LIN_description_file;
LIN_protocol_version = "2.1";
LIN_language_version = "2.1";
LIN_speed = 19.2 kbps;

Nodes {
  Master: MasterNode, 5 ms, 0.1 ms ;
  Slaves: Gateway ;
}

Signals {
  Cluster1Potentiometer1: 8, 0, Gateway, MasterNode;
  Cluster1LightSensor1: 8, 0, Gateway, MasterNode;
  Cluster1Potentiometer2: 8, 0, Gateway, MasterNode;
  Cluster2PotentiometerA: 8, 0, Gateway, MasterNode;
  Cluster2LightSensorA: 8, 0, Gateway, MasterNode;
  Cluster2PotentiometerB: 8, 0, Gateway, MasterNode;
  Cluster2PotentiometerC: 8, 0, Gateway, MasterNode;
  GatewayError: 1, 0, Gateway, MasterNode;
  ClusterIdentifier: 2, 0, MasterNode, Gateway;
}

Frames {
  GatewayControl: 1, MasterNode, 1 {
    ClusterIdentifier, 0;
  }
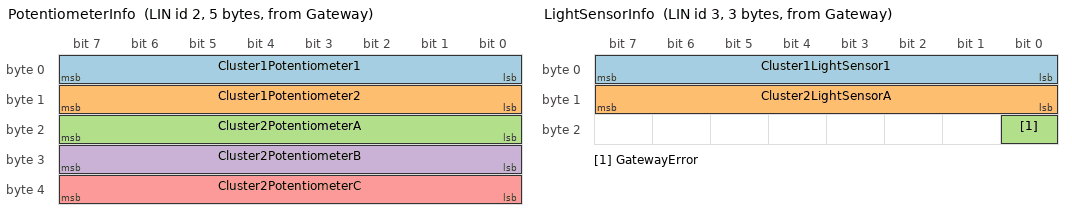
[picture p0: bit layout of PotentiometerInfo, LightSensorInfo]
  PotentiometerInfo: 2, Gateway, 5 {
  Cluster1Potentiometer1, 0;
  Cluster1Potentiometer2, 8;
  Cluster2PotentiometerA, 16;
  Cluster2PotentiometerB, 24;
  Cluster2PotentiometerC, 32;
  }

  LightSensorInfo: 3, Gateway, 3 {
  Cluster1LightSensor1, 0;
  Cluster2LightSensorA, 8;
  GatewayError, 16;
  }
}

Sporadic_frames {
  SporadicControlFrame: GatewayControl;
}

Node_attributes {
  Gateway{
    LIN_protocol = "2.1";
    configured_NAD = 0x1;
    initial_NAD = 0xa;
    product_id = 0x1e, 0x1, 0;
  response_error = GatewayError;
    P2_min = 100 ms;
    ST_min = 20 ms;
    N_As_timeout = 1000 ms;
    N_Cr_timeout = 1000 ms;
    configurable_frames {
    GatewayControl;
      PotentiometerInfo;
    LightSensorInfo;
    SporadicControlFrame;
    }
  }
}

Schedule_tables {
 NormalTable {
    PotentiometerInfo delay 50 ms;
    LightSensorInfo delay 50 ms;
    SporadicControlFrame delay 20 ms;
  }
}
